# otp_reva register map
Registers are access not given, no defined reset value unless marked. A register's access mark holds for its fields unless they carry their own. Offsets are from the block's base; lines under a group give offsets from that group; [hi:lo] are bit positions; {n}, {i} and the like mark numbered series; 'fields as' and 'values as' point back to an identical list; <NAME> marks a mode.

## Memory map
0x40041000 OTP size 0x1000 — One-Time Programmable (OTP) Memory Controller.

## OTP — One-Time Programmable (OTP) Memory Controller.
Base 0x40041000
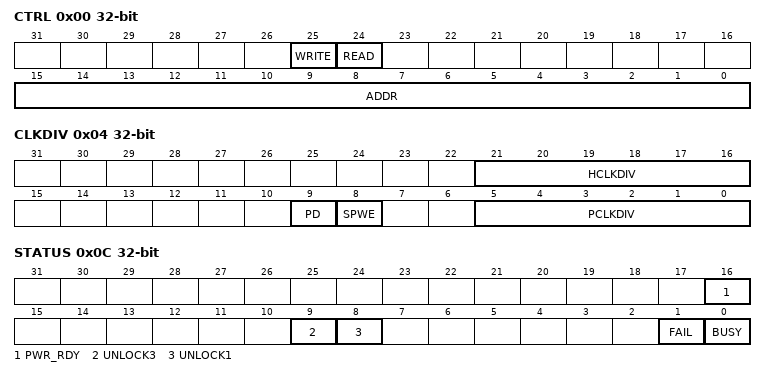
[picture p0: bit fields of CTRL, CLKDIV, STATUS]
0x00 CTRL — OTP Control Register.
  [25] WRITE — Program Operation. Setting this bit starts a write operation from the OTP location specified in the ADDR field.
  [24] READ — Read Operation. Setting this bit starts a read operation from the OTP.
    0=No operation; 1=start (Initiate program operation.)
  [15:0] ADDR — Address of the OTP 32 bit value.
0x04 CLKDIV — OTP Clock Divide Register.
  [21:16] HCLKDIV — Clock Divider. The input clock, HCLK, is divided for generating OTP pwr on and down timing signals.
  [9] PD — Power Down OTP. OTP controller will generate power up and down signals for control pins.
  [8] SPWE — Smart PWE. If programmed value is 1, don't assert PWE.
  [5:0] PCLKDIV — Clock Divider. The input clock, PCLK, is divided for generating OTP timing signals.
    1=DIV2 (Divide by 2); 3=DIV4 (Divide by 4); 7=DIV8 (Divide by 8); 15=DIV16 (Divide by 16); 31=DIV32 (Divide by 32)
0x08 RDATA — GPIO Clear Function Enable Register. Writing a 1 to one or more bits in this register clears the bits in the same positions in GPIO_EN to 0, without affecting other bits in that register.
  [31:0] DATA — OTP Read Data.
0x0C STATUS — OTP Status Register.
  [16] PWR_RDY — OTP Power On Status.
  [9] UNLOCK3 — Unlock3 Flag. This bit indicates that 3 words unlock process is complete.
  [8] UNLOCK1 — Unlock1 Flag. This bit indicates that 1st password was entered, and the user block is enabled for OTP programming.
  [1] FAIL — OTP Failed Flag. This bit indicates whether OTP programming has failed. OTP programming fails if the controller accesses a 32 bit location that has not been previously programmed.
  [0] BUSY — OTP Busy Flag. This bit indicates whether the OTP controller is working a read or write operation.
0x30 WDATA — OTP Write Data Register.
  [31:0] DATA — Write Data.
0x3C ACTRL0 — Access Control for user block.
  [31:0] ADATA — User Block Access Control.
0x40 ACTRL1 — Access Control for sys and user block.
  [31:0] ADATA — System Info Block Access Data.
